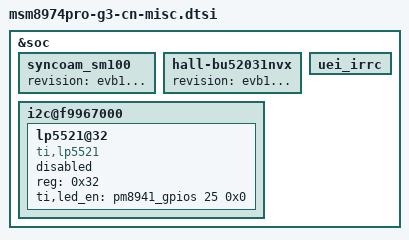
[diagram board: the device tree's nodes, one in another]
/* Copyright (c) 2012, Code Aurora Forum. All rights reserved.
 *
 * This program is free software; you can redistribute it and/or modify
 * it under the terms of the GNU General Public License version 2 and
 * only version 2 as published by the Free Software Foundation.
 *
 * This program is distributed in the hope that it will be useful,
 * but WITHOUT ANY WARRANTY; without even the implied warranty of
 * MERCHANTABILITY or FITNESS FOR A PARTICULAR PURPOSE.  See the
 * GNU General Public License for more details.
 */

&soc {
	syncoam_sm100 {
		status = "ok";
		revision = "evb1...";
	};

	hall-bu52031nvx {
		status = "ok";
		revision = "evb1...";
	};

	uei_irrc {
		status = "ok";
	};

	i2c@f9967000 {
		lp5521@32 {
			compatible = "ti,lp5521";
			status = "disable";
			reg = <0x32>;
			ti,led_en = <&pm8941_gpios 25 0x0>;
		};
	};
};
